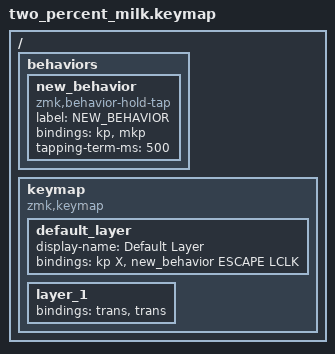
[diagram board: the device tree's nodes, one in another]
/*
 * Copyright (c) 2022 The ZMK Contributors
 *
 * SPDX-License-Identifier: MIT
 */

#include <behaviors.dtsi>
#include <dt-bindings/zmk/keys.h>
#include <dt-bindings/zmk/bt.h>
#include <dt-bindings/zmk/pointing.h>


/ {
    behaviors {
        new_behavior: new_behavior {
            compatible = "zmk,behavior-hold-tap";
            label = "NEW_BEHAVIOR";
            bindings = <&kp>, <&mkp>;

            #binding-cells = <2>;
            tapping-term-ms = <500>;
        };
    };

    keymap {
        compatible = "zmk,keymap";

        default_layer {
            display-name = "Default Layer";
            bindings = <
&kp X  &new_behavior ESCAPE LCLK
            >;
        };

        layer_1 {
            bindings = <
&trans  &trans
            >;
        };
    };
};
